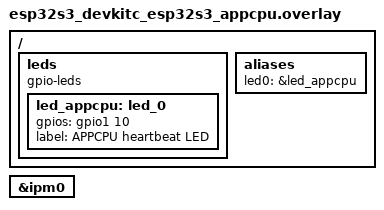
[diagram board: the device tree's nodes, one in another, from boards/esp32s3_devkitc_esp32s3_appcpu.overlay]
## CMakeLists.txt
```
cmake_minimum_required(VERSION 3.20.0)

find_package(Zephyr REQUIRED HINTS $ENV{ZEPHYR_BASE})
project(01_hello_dualcore_appcpu)

target_sources(app PRIVATE src/main.c)
```

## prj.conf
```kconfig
# 01_HELLO_DUALCORE_LAB - core1 (appcpu) image
#
# No CONFIG_LOG / console here on purpose: Zephyr's UART console driver is
# not yet available on the ESP32-S3 appcpu image, so any log call here
# would either fail to build against a usable backend or simply produce
# no visible output. This core proves itself alive with a GPIO LED only -
# see doc/01_HELLO_DUALCORE_LAB_KR.md section on this limitation.

CONFIG_GPIO=y

# Required even though this lab has no IPC of its own: on this board,
# appcpu is never released from reset unless &ipm0 is enabled on BOTH
# images (confirmed on real hardware - see the troubleshooting doc for
# how this was found). Not used to send/receive anything here.
CONFIG_IPM=y
CONFIG_ESP32_SOFT_IPM=y
```

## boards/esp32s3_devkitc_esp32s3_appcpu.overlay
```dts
/*
 * Overlay for 01_HELLO_DUALCORE_LAB - core1 (appcpu) image
 *
 * Same "gpio-leds" / `led0` alias pattern as the procpu overlay, on a
 * different GPIO so both LEDs are visually distinguishable on the
 * breadboard.
 *
 * GPIO42 is a plain, unused GPIO on this board (not a strapping pin
 * 0/3/45/46, not USB-JTAG 19/20, not in the SPI flash range 26-32 or the
 * octal PSRAM/flash range 33-37) - chosen freely for this lab and
 * intended as this IPC track's convention for the appcpu heartbeat LED
 * in later labs too. GPIO42 is >= GPIO32, so it lives on the &gpio1
 * controller (pins 32-53) at local index 42-32=10.
 *
 * GPIO39-42 double as the classic 5-pin external JTAG (MTCK/MTDO/MTDI/
 * MTMS) on ESP32-S3, but DevKitC-1 boards use the separate USB-JTAG
 * bridge on GPIO19/20 instead, so GPIO42 is free for general GPIO use
 * here.
 */

#include <zephyr/dt-bindings/gpio/gpio.h>

/ {
	leds {
		compatible = "gpio-leds";
		led_appcpu: led_0 {
			gpios = <&gpio1 10 GPIO_ACTIVE_HIGH>;
			label = "APPCPU heartbeat LED";
		};
	};

	aliases {
		led0 = &led_appcpu;
	};
};

/*
 * Required even though this lab has no IPC of its own: on this board,
 * appcpu is never released from reset unless &ipm0 is enabled on BOTH
 * images (confirmed on real hardware - see the troubleshooting doc for
 * how this was found). Not used to send/receive anything here - Lab 02
 * is where this project starts actually using inter-core communication.
 */
&ipm0 {
	status = "okay";
};
```

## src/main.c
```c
/*
 * main.c - 01_HELLO_DUALCORE_LAB (core1 / appcpu image)
 *
 * This core does exactly one job: blink its own LED, on its own clock,
 * with no coordination with core0 at all. There is no IPC in this lab -
 * both images just happen to be flashed onto the same chip and run at
 * the same time. Lab 02 is where the two cores start actually talking.
 *
 * Deliberately no logging/console output here: Zephyr's UART console
 * driver is not yet available on the ESP32-S3 appcpu image (see this
 * board's Zephyr documentation and this lab's KR/EN doc for details), so
 * a LOG_INF() call here would have nowhere to go. The LED is the only
 * proof-of-life this core has - which is the whole point of this lab.
 *
 * Blink period is intentionally different from core0's (200ms vs 500ms)
 * so the two LEDs are visually distinguishable as running independently,
 * not in lock-step.
 */

#include <zephyr/kernel.h>
#include <zephyr/drivers/gpio.h>

static const struct gpio_dt_spec led = GPIO_DT_SPEC_GET(DT_ALIAS(led0), gpios);

#define BLINK_PERIOD_MS 200

int main(void)
{
	if (!gpio_is_ready_dt(&led)) {
		/* No console to log to - nothing more useful to do than
		 * return and let the board stay silent/idle, which itself
		 * is a symptom to look for if the LED never lights up.
		 */
		return -1;
	}

	int ret = gpio_pin_configure_dt(&led, GPIO_OUTPUT_INACTIVE);

	if (ret) {
		return -1;
	}

	bool led_state = false;

	while (1) {
		led_state = !led_state;
		gpio_pin_set_dt(&led, led_state);
		k_msleep(BLINK_PERIOD_MS);
	}

	return 0;
}
```
